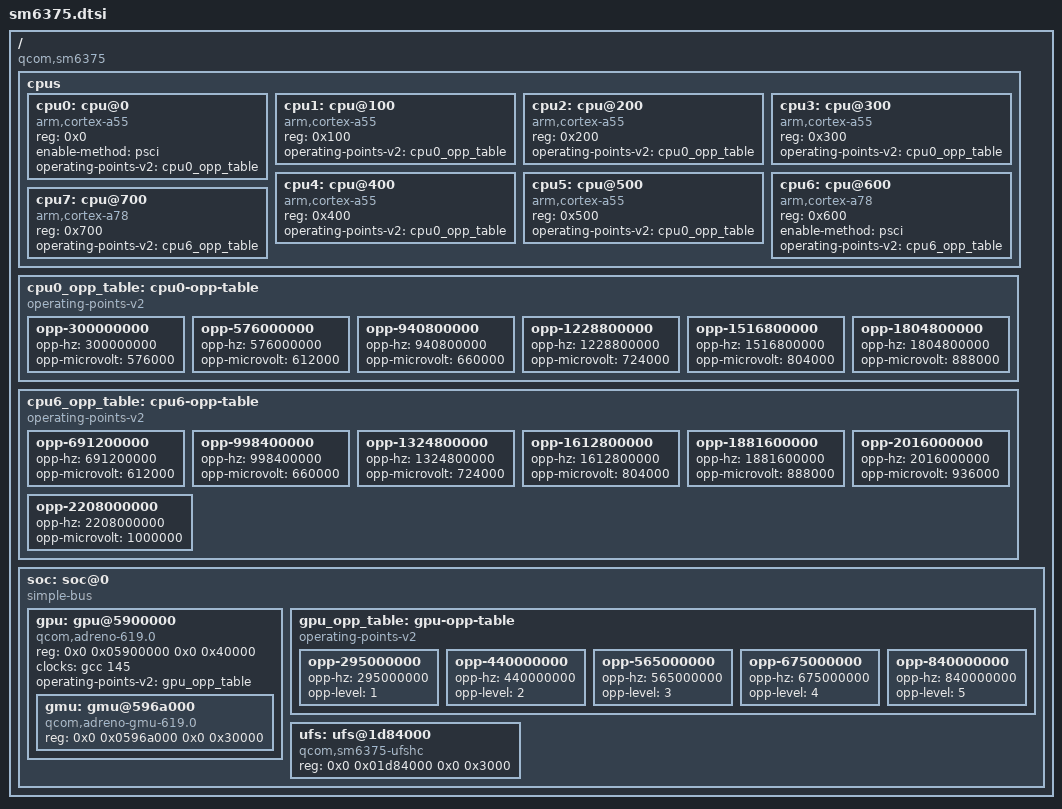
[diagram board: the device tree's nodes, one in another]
// SPDX-License-Identifier: GPL-2.0
/*
 * Qualcomm Technologies, Inc. SM6375 (Snapdragon 695 5G)
 * Reference: POCO X4 Pro 5G / Redmi Note 11 Pro 5G (Veux / Peux)
 * Source: MiCode/Xiaomi_Kernel_OpenSource (veux-s-oss)
 */

/ {
	compatible = "qcom,sm6375";
	#address-cells = <2>;
	#size-cells = <2>;

	cpus {
		#address-cells = <1>;
		#size-cells = <0>;

		/* Silver / Little Cluster: 6x Kryo 660 Silver (Cortex-A55) up to 1.8 GHz */
		cpu0: cpu@0 {
			device_type = "cpu";
			compatible = "arm,cortex-a55";
			reg = <0x0>;
			enable-method = "psci";
			operating-points-v2 = <&cpu0_opp_table>;
		};
		cpu1: cpu@100 {
			device_type = "cpu";
			compatible = "arm,cortex-a55";
			reg = <0x100>;
			operating-points-v2 = <&cpu0_opp_table>;
		};
		cpu2: cpu@200 {
			device_type = "cpu";
			compatible = "arm,cortex-a55";
			reg = <0x200>;
			operating-points-v2 = <&cpu0_opp_table>;
		};
		cpu3: cpu@300 {
			device_type = "cpu";
			compatible = "arm,cortex-a55";
			reg = <0x300>;
			operating-points-v2 = <&cpu0_opp_table>;
		};
		cpu4: cpu@400 {
			device_type = "cpu";
			compatible = "arm,cortex-a55";
			reg = <0x400>;
			operating-points-v2 = <&cpu0_opp_table>;
		};
		cpu5: cpu@500 {
			device_type = "cpu";
			compatible = "arm,cortex-a55";
			reg = <0x500>;
			operating-points-v2 = <&cpu0_opp_table>;
		};

		/* Gold / Performance Cluster: 2x Kryo 660 Gold (Cortex-A78) up to 2.2 GHz */
		cpu6: cpu@600 {
			device_type = "cpu";
			compatible = "arm,cortex-a78";
			reg = <0x600>;
			enable-method = "psci";
			operating-points-v2 = <&cpu6_opp_table>;
		};
		cpu7: cpu@700 {
			device_type = "cpu";
			compatible = "arm,cortex-a78";
			reg = <0x700>;
			operating-points-v2 = <&cpu6_opp_table>;
		};
	};

	cpu0_opp_table: cpu0-opp-table {
		compatible = "operating-points-v2";
		opp-300000000  { opp-hz = /bits/ 64 <300000000>;  opp-microvolt = <576000>; };
		opp-576000000  { opp-hz = /bits/ 64 <576000000>;  opp-microvolt = <612000>; };
		opp-940800000  { opp-hz = /bits/ 64 <940800000>;  opp-microvolt = <660000>; };
		opp-1228800000 { opp-hz = /bits/ 64 <1228800000>; opp-microvolt = <724000>; };
		opp-1516800000 { opp-hz = /bits/ 64 <1516800000>; opp-microvolt = <804000>; };
		opp-1804800000 { opp-hz = /bits/ 64 <1804800000>; opp-microvolt = <888000>; };
	};

	cpu6_opp_table: cpu6-opp-table {
		compatible = "operating-points-v2";
		opp-691200000  { opp-hz = /bits/ 64 <691200000>;  opp-microvolt = <612000>; };
		opp-998400000  { opp-hz = /bits/ 64 <998400000>;  opp-microvolt = <660000>; };
		opp-1324800000 { opp-hz = /bits/ 64 <1324800000>; opp-microvolt = <724000>; };
		opp-1612800000 { opp-hz = /bits/ 64 <1612800000>; opp-microvolt = <804000>; };
		opp-1881600000 { opp-hz = /bits/ 64 <1881600000>; opp-microvolt = <888000>; };
		opp-2016000000 { opp-hz = /bits/ 64 <2016000000>; opp-microvolt = <936000>; };
		opp-2208000000 { opp-hz = /bits/ 64 <2208000000>; opp-microvolt = <1000000>; };
	};

	soc: soc@0 {
		compatible = "simple-bus";
		#address-cells = <2>;
		#size-cells = <2>;

		/* Adreno 619 with Graphics Management Unit (GMU) */
		gpu: gpu@5900000 {
			compatible = "qcom,adreno-619.0", "qcom,adreno";
			reg = <0x0 0x05900000 0x0 0x40000>;
			clocks = <&gcc 145>;
			operating-points-v2 = <&gpu_opp_table>;

			/* GMU Subsystem */
			gmu: gmu@596a000 {
				compatible = "qcom,adreno-gmu-619.0", "qcom,adreno-gmu";
				reg = <0x0 0x0596a000 0x0 0x30000>;
			};
		};

		gpu_opp_table: gpu-opp-table {
			compatible = "operating-points-v2";
			opp-295000000 { opp-hz = /bits/ 64 <295000000>; opp-level = <1>; };
			opp-440000000 { opp-hz = /bits/ 64 <440000000>; opp-level = <2>; };
			opp-565000000 { opp-hz = /bits/ 64 <565000000>; opp-level = <3>; };
			opp-675000000 { opp-hz = /bits/ 64 <675000000>; opp-level = <4>; };
			opp-840000000 { opp-hz = /bits/ 64 <840000000>; opp-level = <5>; };
		};

		/* UFS 2.2 Storage Controller */
		ufs: ufs@1d84000 {
			compatible = "qcom,sm6375-ufshc", "qcom,ufshc";
			reg = <0x0 0x01d84000 0x0 0x3000>;
		};
	};
};
